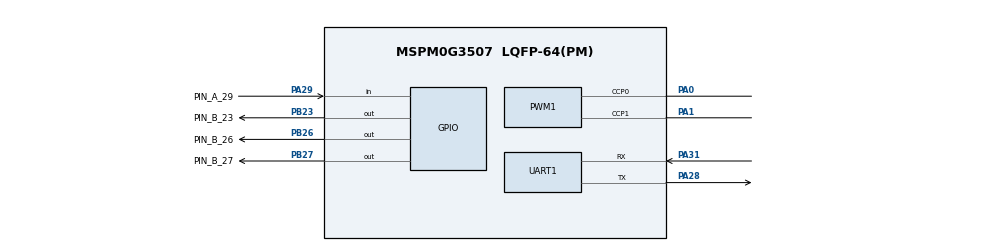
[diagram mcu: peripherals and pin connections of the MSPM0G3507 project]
/**
 * These arguments were used when this file was generated. They will be automatically applied on subsequent loads
 * via the GUI or CLI. Run CLI with '--help' for additional information on how to override these arguments.
 * @cliArgs --device "MSPM0G350X" --part "Default" --package "LQFP-64(PM)" --product "mspm0_sdk@2.05.01.00"
 * @v2CliArgs --device "MSPM0G3507" --package "LQFP-64(PM)" --product "mspm0_sdk@2.05.01.00"
 * @versions {"tool":"1.24.0+4110"}
 */

/**
 * Import the modules used in this configuration.
 */
const GPIO   = scripting.addModule("/ti/driverlib/GPIO", {}, false);
const GPIO1  = GPIO.addInstance();
const GPIO2  = GPIO.addInstance();
const GPIO3  = GPIO.addInstance();
const GPIO4  = GPIO.addInstance();
const PWM    = scripting.addModule("/ti/driverlib/PWM", {}, false);
const PWM1   = PWM.addInstance();
const SYSCTL = scripting.addModule("/ti/driverlib/SYSCTL");
const UART   = scripting.addModule("/ti/driverlib/UART", {}, false);
const UART1  = UART.addInstance();

/**
 * Write custom configuration values to the imported modules.
 */
const divider9       = system.clockTree["UDIV"];
divider9.divideValue = 2;

const gate7  = system.clockTree["MFCLKGATE"];
gate7.enable = true;

const mux4       = system.clockTree["EXHFMUX"];
mux4.inputSelect = "EXHFMUX_XTAL";

const mux8       = system.clockTree["HSCLKMUX"];
mux8.inputSelect = "HSCLKMUX_SYSPLL2X";

const mux12       = system.clockTree["SYSPLLMUX"];
mux12.inputSelect = "zSYSPLLMUX_HFCLK";

const pinFunction4       = system.clockTree["HFXT"];
pinFunction4.inputFreq   = 40;
pinFunction4.enable      = true;
pinFunction4.HFXTStartup = 10;

GPIO1.port                          = "PORTB";
GPIO1.$name                         = "GPIO_GRP_LED";
GPIO1.associatedPins[0].assignedPin = "22";
GPIO1.associatedPins[0].$name       = "PIN_B_22";

const Board = scripting.addModule("/ti/driverlib/Board", {}, false);

GPIO2.port                          = "PORTA";
GPIO2.$name                         = "GPIO_GRP_MOTOR";
GPIO2.associatedPins.create(3);
GPIO2.associatedPins[0].assignedPin = "24";
GPIO2.associatedPins[0].$name       = "PIN_A_24";
GPIO2.associatedPins[1].assignedPin = "25";
GPIO2.associatedPins[1].$name       = "PIN_A_25";
GPIO2.associatedPins[2].assignedPin = "26";
GPIO2.associatedPins[2].$name       = "PIN_A_26";

GPIO3.port                          = "PORTA";
GPIO3.$name                         = "GPIO_GRP_ENCODER";
GPIO3.associatedPins.create(4);
GPIO3.associatedPins[0].assignedPin = "14";
GPIO3.associatedPins[0].direction   = "INPUT";
GPIO3.associatedPins[0].interruptEn = true;
GPIO3.associatedPins[0].polarity    = "RISE";
GPIO3.associatedPins[0].$name       = "PIN_A_14";
GPIO3.associatedPins[1].assignedPin = "15";
GPIO3.associatedPins[1].direction   = "INPUT";
GPIO3.associatedPins[1].$name       = "PIN_A_15";
GPIO3.associatedPins[2].assignedPin = "16";
GPIO3.associatedPins[2].direction   = "INPUT";
GPIO3.associatedPins[2].interruptEn = true;
GPIO3.associatedPins[2].polarity    = "RISE";
GPIO3.associatedPins[2].$name       = "PIN_A_16";
GPIO3.associatedPins[3].assignedPin = "17";
GPIO3.associatedPins[3].direction   = "INPUT";
GPIO3.associatedPins[3].$name       = "PIN_A_17";

GPIO4.$name                          = "GPIO_GRP_IRS";
GPIO4.associatedPins.create(4);
GPIO4.associatedPins[0].assignedPin  = "23";
GPIO4.associatedPins[0].$name        = "PIN_B_23";
GPIO4.associatedPins[0].assignedPort = "PORTB";
GPIO4.associatedPins[0].pin.$assign  = "PB23";
GPIO4.associatedPins[1].assignedPin  = "26";
GPIO4.associatedPins[1].$name        = "PIN_B_26";
GPIO4.associatedPins[1].assignedPort = "PORTB";
GPIO4.associatedPins[1].pin.$assign  = "PB26";
GPIO4.associatedPins[2].$name        = "PIN_B_27";
GPIO4.associatedPins[2].assignedPin  = "27";
GPIO4.associatedPins[2].assignedPort = "PORTB";
GPIO4.associatedPins[2].pin.$assign  = "PB27";
GPIO4.associatedPins[3].$name        = "PIN_A_29";
GPIO4.associatedPins[3].direction    = "INPUT";
GPIO4.associatedPins[3].assignedPort = "PORTA";
GPIO4.associatedPins[3].assignedPin  = "29";
GPIO4.associatedPins[3].pin.$assign  = "PA29";

PWM1.$name                      = "PWM_0";
PWM1.clockDivider               = 4;
PWM1.clockPrescale              = 20;
PWM1.pwmMode                    = "EDGE_ALIGN_UP";
PWM1.enableShadowLoad           = true;
PWM1.peripheral.$assign         = "TIMA0";
PWM1.peripheral.ccp0Pin.$assign = "PA0";
PWM1.peripheral.ccp1Pin.$assign = "PA1";
PWM1.PWM_CHANNEL_0.$name        = "ti_driverlib_pwm_PWMTimerCC0";
PWM1.PWM_CHANNEL_1.$name        = "ti_driverlib_pwm_PWMTimerCC1";
PWM1.ccp0PinConfig.$name        = "ti_driverlib_gpio_GPIOPinGeneric2";
PWM1.ccp1PinConfig.$name        = "ti_driverlib_gpio_GPIOPinGeneric3";

SYSCTL.forceDefaultClkConfig = true;
SYSCTL.clockTreeEn           = true;
scripting.suppress("For best practices when the CPUCLK is running at 32MHz and above, clear the flash status bit using DL_FlashCTL_executeClearStatus\\(\\) before executing any flash operation\\. Otherwise there may be false positives\\.", SYSCTL);

UART1.$name                             = "UART_0";
UART1.targetBaudRate                    = 100000;
UART1.uartClkSrc                        = "MFCLK";
UART1.enableFIFO                        = true;
UART1.rxFifoThreshold                   = "DL_UART_RX_FIFO_LEVEL_ONE_ENTRY";
UART1.enabledDMARXTriggers              = "DL_UART_DMA_INTERRUPT_RX";
UART1.txFifoThreshold                   = "DL_UART_TX_FIFO_LEVEL_ONE_ENTRY";
UART1.enabledDMATXTriggers              = "DL_UART_DMA_INTERRUPT_TX";
UART1.enabledInterrupts                 = ["DMA_DONE_RX","DMA_DONE_TX","EOT_DONE","RX_TIMEOUT_ERROR"];
UART1.peripheral.$assign                = "UART0";
UART1.peripheral.rxPin.$assign          = "PA31";
UART1.peripheral.txPin.$assign          = "PA28";
UART1.txPinConfig.$name                 = "ti_driverlib_gpio_GPIOPinGeneric0";
UART1.rxPinConfig.$name                 = "ti_driverlib_gpio_GPIOPinGeneric1";
UART1.DMA_CHANNEL_RX.$name              = "DMA_CH0";
UART1.DMA_CHANNEL_RX.addressMode        = "f2b";
UART1.DMA_CHANNEL_RX.srcLength          = "BYTE";
UART1.DMA_CHANNEL_RX.dstLength          = "BYTE";
UART1.DMA_CHANNEL_RX.peripheral.$assign = "DMA_CH0";
UART1.DMA_CHANNEL_TX.$name              = "DMA_CH1";
UART1.DMA_CHANNEL_TX.addressMode        = "b2f";
UART1.DMA_CHANNEL_TX.srcLength          = "BYTE";
UART1.DMA_CHANNEL_TX.dstLength          = "BYTE";

/**
 * Pinmux solution for unlocked pins/peripherals. This ensures that minor changes to the automatic solver in a future
 * version of the tool will not impact the pinmux you originally saw.  These lines can be completely deleted in order to
 * re-solve from scratch.
 */
pinFunction4.peripheral.$suggestSolution           = "SYSCTL";
pinFunction4.peripheral.hfxInPin.$suggestSolution  = "PA5";
pinFunction4.peripheral.hfxOutPin.$suggestSolution = "PA6";
GPIO1.associatedPins[0].pin.$suggestSolution       = "PB22";
Board.peripheral.$suggestSolution                  = "DEBUGSS";
Board.peripheral.swclkPin.$suggestSolution         = "PA20";
Board.peripheral.swdioPin.$suggestSolution         = "PA19";
GPIO2.associatedPins[0].pin.$suggestSolution       = "PA24";
GPIO2.associatedPins[1].pin.$suggestSolution       = "PA25";
GPIO2.associatedPins[2].pin.$suggestSolution       = "PA26";
GPIO3.associatedPins[0].pin.$suggestSolution       = "PA14";
GPIO3.associatedPins[1].pin.$suggestSolution       = "PA15";
GPIO3.associatedPins[2].pin.$suggestSolution       = "PA16";
GPIO3.associatedPins[3].pin.$suggestSolution       = "PA17";
UART1.DMA_CHANNEL_TX.peripheral.$suggestSolution   = "DMA_CH1";
